# ATtiny44A register map
Vendor: Atmel; File version: 1.0
CPU: other r0p0, little endian, no MPU, no FPU, 4 interrupt priority bits
Registers are 8-bit, read-write, reset 0x0 unless marked. A register's access mark holds for its fields unless they carry their own. Offsets are from the block's base; lines under a group give offsets from that group; [hi:lo] are bit positions; {n}, {i} and the like mark numbered series; 'fields as' and 'values as' point back to an identical list; <NAME> marks a mode.

## Memory map
0x00800020 CPU blocks up to offset 0x40 — CPU Registers
0x00800021 AC blocks up to offset 0x8 — Analog Comparator
0x00800021 ADC blocks up to offset 0x7 — Analog-to-Digital Converter
0x0080002B TC1 blocks up to offset 0x25 — Timer/Counter, 16-bit
0x0080002D USI size 0x4 — Universal Serial Interface
0x00800032 EXINT blocks up to offset 0x2A — External Interrupts
0x00800036 PORTB size 0x3 — I/O Port
0x00800039 PORTA size 0x3 — I/O Port
0x0080003C EEPROM size 0x4
0x00800041 WDT size 0x1 — Watchdog Timer
0x00800043 TC0 blocks up to offset 0x1A — Timer/Counter, 8-bit
0x00800057 BOOT_LOAD size 0x1 — Bootloader

## Interrupts
0 RESET (CPU) — External Pin, Power-on Reset, Brown-out Reset,Watchdog Reset
1 EXT_INT0 (CPU) — External Interrupt Request 0
2 PCINT0 (CPU) — Pin Change Interrupt Request 0
3 PCINT1 (CPU) — Pin Change Interrupt Request 1
4 WDT (CPU) — Watchdog Time-out
5 TIM1_CAPT (CPU) — Timer/Counter1 Capture Event
6 TIM1_COMPA (CPU) — Timer/Counter1 Compare Match A
7 TIM1_COMPB (CPU) — Timer/Counter1 Compare Match B
8 TIM1_OVF (CPU) — Timer/Counter1 Overflow
9 TIM0_COMPA (CPU) — Timer/Counter0 Compare Match A
10 TIM0_COMPB (CPU) — Timer/Counter0 Compare Match B
11 TIM0_OVF (CPU) — Timer/Counter0 Overflow
12 ANA_COMP (CPU) — Analog Comparator
13 ADC (CPU) — ADC Conversion Complete
14 EE_RDY (CPU) — EEPROM Ready
15 USI_STR (CPU) — USI START
16 USI_OVF (CPU) — USI Overflow

## AC — Analog Comparator
Base 0x00800021
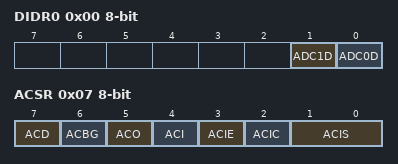
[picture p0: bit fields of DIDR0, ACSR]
0x00 DIDR0
  [1] ADC1D — ADC 1 Digital input buffer disable
  [0] ADC0D — ADC 0 Digital input buffer disable
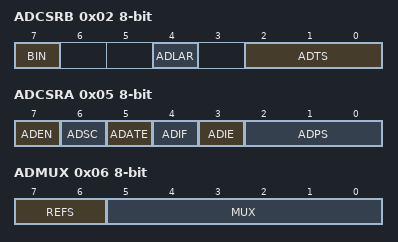
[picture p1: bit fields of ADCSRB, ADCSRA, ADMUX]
0x02 ADCSRB — ADC Control and Status Register B
  [6] ACME — Analog Comparator Multiplexer Enable
0x07 ACSR — Analog Comparator Control And Status Register (read-only for debugger)
  [7] ACD — Analog Comparator Disable
  [6] ACBG — Analog Comparator Bandgap Select
  [5] ACO — Analog Compare Output
  [4] ACI — Analog Comparator Interrupt Flag
  [3] ACIE — Analog Comparator Interrupt Enable
  [2] ACIC — Analog Comparator Input Capture Enable
  [1:0] ACIS — Analog Comparator Interrupt Mode Select bits
    0=INTERRUPT_ON_TOGGLE; 2=INTERRUPT_ON_FALLING_EDGE; 3=INTERRUPT_ON_RISING_EDGE

## ADC — Analog-to-Digital Converter
Base 0x00800021
0x00 DIDR0 — Digital Input Disable Register 0
0x02 ADCSRB — ADC Control and Status Register B
  [7] BIN — Bipolar Input Mode
  [4] ADLAR — ADC Left Adjust Result
  [2:0] ADTS — ADC Auto Trigger Source bits
    0=FREE_RUNNING_MODE; 1=ANALOG_COMPARATOR; 2=EXTERNAL_INTERRUPT_REQUEST_0; 3=TIMER_COUNTER0_COMPARE_MATCH_A; 4=TIMER_COUNTER0_OVERFLOW; 5=TIMER_COUNTER1_COMPARE_MATCH_B; 6=TIMER_COUNTER1_OVERFLOW; 7=TIMER_COUNTER1_CAPTURE_EVENT
0x03 ADC 16-bit (reset mask 0xFF) — ADC Data Register Bytes
0x05 ADCSRA — ADC Control and Status Register A (read-only for debugger)
  [7] ADEN — ADC Enable
  [6] ADSC — ADC Start Conversion
  [5] ADATE — ADC Auto Trigger Enable
  [4] ADIF — ADC Interrupt Flag
  [3] ADIE — ADC Interrupt Enable
  [2:0] ADPS — ADC Prescaler Select Bits
    1=2; 2=4; 3=8; 4=16; 5=32; 6=64; 7=128
0x06 ADMUX — ADC Multiplexer Selection Register
  [7:6] REFS — Reference Selection Bits
    0=VCC_USED_AS_ANALOG_REFERENCE_DISCONNECTED_FROM_PA0_AREF; 1=EXTERNAL_VOLTAGE_REFERENCE_AT_PA0_AREF_PIN_INTERNAL_REFERENCE_TURNED_OFF; 2=INTERNAL_1_1V_VOLTAGE_REFERENCE
  [5:0] MUX — Analog Channel and Gain Selection Bits

## BOOT_LOAD — Bootloader
Base 0x00800057
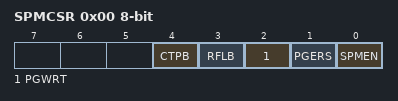
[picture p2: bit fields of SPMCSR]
0x00 SPMCSR — Store Program Memory Control Register (read-only for debugger)
  [4] CTPB — Clear temporary page buffer
  [3] RFLB — Read fuse and lock bits
  [2] PGWRT — Page Write
  [1] PGERS — Page Erase
  [0] SPMEN — Store Program Memory Enable
